# nrf5002 register map
Vendor: Nordic Semiconductor; Series: nRF50; File version: 1
CPU: CM0 r0p4, little endian, no MPU, no FPU, 2 interrupt priority bits, 32 interrupts
Registers are 32-bit, read-write, reset 0x0 unless marked. A register's access mark holds for its fields unless they carry their own. Offsets are from the block's base; [hi:lo] are bit positions; lines under a group give offsets from that group; 'fields as' and 'values as' point back to an identical list.

## REGULATORS — Regulator control
Base 0x40001000; alternate view of OSCILLATORS
0x434 DISABLEHPBOR wo — Enable or disable HPBOR
  [0] DISABLE
    0=Enabled (Enable HPBOR); 1=Disabled (Disable HPBOR)
0x500 SYSTEMOFF wo
  [0] SYSTEMOFF — Enable System OFF mode
    1=Enter (Enable System OFF mode)
0x50C POFSTAT ro — Power-fail comparator status register
  [0] COMPARATOR — Power-fail comparator status
    0=Above (Detected voltage is above VPOF threshold); 1=Below (Detected voltage is below VPOF threshold.)
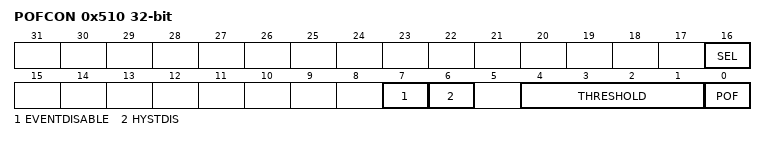
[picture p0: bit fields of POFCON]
0x510 POFCON — Power-fail comparator configuration
  [16] SEL — Power-fail comparator input selector
    0=VDD (POF measures or monitors the VDD supply voltage pin); 1=VMON (POF measures or monitors the VDDL pin.)
  [7] EVENTDISABLE — Disable the POFWARN power-fail warning event
    0=Enabled (POFWARN event is generated.); 1=Disabled (POFWARN event is not generated.)
  [6] HYSTDIS — Bypass power-fail comparator hysteresis
    0=Normal (Hysteresis active); 1=NoHyst (Hysteresis disabled)
  [4:1] THRESHOLD — Power-fail comparator threshold setting
    0=V17 (Set threshold to 1.7 V for VBUS, or 0.90 V for VDD); 1=V18 (Set threshold to 1.8 V for VBUS, or 0.95 V for VDD); 2=V19 (Set threshold to 1.9 V for VBUS, or 1.00 V for VDD); 3=V20 (Set threshold to 2.0 V for VBUS, or 1.05 V for VDD); 4=V21 (Set threshold to 2.1 V for VBUS, or 1.10 V for VDD); 5=V22 (Set threshold to 2.2 V for VBUS, or 1.15 V for VDD); 6=V23 (Set threshold to 2.3 V for VBUS, or 1.20 V for VDD); 7=V24 (Set threshold to 2.4 V for VBUS, or 1.25 V for VDD); 8=V25 (Set threshold to 2.5 V for VBUS, or 1.30 V for VDD); 9=V26 (Set threshold to 2.6 V for VBUS, or 1.35 V for VDD); 10=V27 (Set threshold to 2.7 V for VBUS, or 1.40 V for VDD); 11=V28 (Set threshold to 2.8 V for VBUS, or 1.45 V for VDD); 12=V29 (Set threshold to 2.9 V for VBUS, or 1.50 V for VDD); 13=V30 (Set threshold to 3.0 V for VBUS, or 1.55 V for VDD); 14=V31 (Set threshold to 3.1 V for VBUS, or 1.60 V for VDD); 15=V32 (Set threshold to 3.2 V for VBUS, or 1.65 V for VDD)
  [0] POF — Enable or disable power-fail comparator
    0=Disabled; 1=Enabled
0x514 IGNOREDAPCPWRREGMODE wo — Ignore DAPCP power mode
  [0] IGNOREDAPCPWRREGMODE — Ignore power request from debugger
    0=Do not ignore power request from debugger; 1=Ignore power request from debugger
0x518 RSTVTHTRIM — Threshold trim, power-on reset
  [4:0] RSTVTHTRIM
0x520 BGREFTRIM — Master bias bandgap trim
  [3:0] BGREFTRIM — Threshold trim, brown-out reset for VDDL battery
0x588 ATEPOWER reset 0x1 — Analog test bus control for power modules
0x58C VREFULPTRIM — Trim value of VREF_ULP
  [3:0] VREFULPTRIM — Trim value of VREF_ULP Default 4'b0011
0x5E8 FORCEVBUSDET — Force VBUS detection indication
  [1:0] FORCEVBUSDET — Force VBUS detection indication, overriding the analog detection circuitry
    0=Do not force VBUS detection output; 1=ForceNoVbusDet (Force detection output to 'no VBUS present'); 2=DoNotForce2 (Do not force VBUS detection output (same effect as DoNotForce)); 3=ForceVbusDet (Force detection output to 'VBUS present')
0x900 VREGANA group — Unspecified
  0x00 VOUT — Control the output voltage
    [1:0] VOUT — Output voltage
      0=1.0 V; 1=1.05 V; 2=1.10 V; 3=1.20 V
  0x04 DCDCEN — Enable DC/DC operation of the regulator
    [0] DCDCEN — Enable or disable DC/DC converter
      0=Disabled; 1=Enabled
  0x08 ENFORCEPWRREGMODE — Enable forcing of power mode in power regulator
    [0] ENFORCEPWRREGMODE
      0=Disabled (Power regulator forcing off); 1=Enabled (Power regulator mode forced to value given by FORCEREGMODE)
  0x0C FORCEREGMODE — Backdoor register for manual selection of power mode
    [2:0] FORCEREGMODE — Force regulator mode to value
      0=Ext (Force external); 1=ULP (Force ULP mode); 2=LDO (Force LDO mode); 3=DCDC (Force DC/DC mode); 4=REF (Force REF mode)
  0x10 CURRENTPWRREGMODE ro — Current mode in the power regulator
    [3:0] CURRENTPWRREGMODE
      0=Ext (External); 2=DCDC; 3=REF; 4=LDO (ULP DC/DC); 6=LDO_DCDC; 7=LDO_REF; 8=ULP; 10=DCDC_ULP (ULP DC/DC); 11=REF_ULP; 12=ULP_LDO (ULP DC/DC)
  0x14 TESTLOAD — Test load setting
    [2:0] TESTLOAD — Output load configuration (for test purposes)
      0=Normal operation (default); 1=1mATestLoad; 2=20mATestLoad
  0x18 ULPCAL — Calibration of ULP regulator
    [3:0] CAL — Calibration value
  0x1C DEBUGLVLP — Debug register - control spare signals in LVLP
    [13:0] DEBUGLVLP — Connected to TBD
  0x24 BUCKCALMAXILIM
    [1:0] CALMAXILIM
  0x28 BUCKCALPWM
    [4:0] CALPWM
  0x2C BUCKPFMEN reset 0x1 — PFM enable register
    [0] PFMEN — Enable or disable PFM
      0=Disabled (Disable PFM); 1=Enabled (Enable PFM (default))
  0x30 BUCKPFMCAL
    [3:0] PFMCAL
  0x34 BUCKPFMICMPCAL
    [2:0] PFMICMPCAL
  0x38 BUCKPFMICMPCOUNT
    [15:0] PFMICMPCOUNT
  0x3C PWRREGTHRESHOLD — Set threshold value of power regulator
    [6:0] PWRREGTHRESHOLD — Sets the threshold value of power regulator
  0x40 AVOIDULP reset 0x1 — Backdoor to avoid ULP mode
    [0] ENABLE
      0=Default (FSM will enter ULP mode if no power requests are present.); 1=AvoidUlp (Avoids ULP mode. By also setting disableDcdcDvdd=0 and disablePfmDvdd=0, PFM mode will be used as the lowest power regulator state.)
0xA00 VREGMAIN group — Unspecified
  0x00 VOUT — Control the output voltage
    [3:0] VOUT — Output voltage
  0x04 ULPALWAYSON reset 0x1 — Keep ULP regulator on at all times
    [0] ULPALWAYSON
      0=Disabled (ULP regulator turned off in LDO modes); 1=Enabled (ULP regulator always on)
  0x08 ENFORCEPWRREGMODE — Enable forcing of power mode in power regulator
    fields as VREGANA.ENFORCEPWRREGMODE
  0x0C FORCEREGMODE — Backdoor register for manual selection of power mode
    fields as VREGANA.FORCEREGMODE
  0x10 CURRENTPWRREGMODE ro — Current mode in the power regulator
    fields as VREGANA.CURRENTPWRREGMODE
  0x14 PWRREGICMPTIMER — Control the stay-alive time for the current comparator
    [15:0] COUNT
  0x18 TESTLOAD — Test load setting
    [2:0] TESTLOAD — Output load configuration for test purposes
      0=Normal operation (default); 1=1mATestLoad; 2=20mATestLoad
  0x20 ULPCAL — Calibration of ULP regulator
    [3:0] CAL — Calibration value
  0x24 ULPICMPCAL — Calibration of current comparator on ULP regulator
    [2:0] CAL
  0x28 BYPASS — Bypass control
    [0] CAL
      0=NormalMode (Normal operation (default)); 1=BypassMode (Output voltage is 30 mV lower than input voltage)
0xEE4 DISABLEPACSYSTEMOFFACK wo — Enable or disable System OFF ack from PAC
  [0] DISABLE
    0=Enabled (Enable ack); 1=Disabled (Disable ack)
0xEE8 DISABLESRAMSYSTEMOFFACK wo — Enable or disable System OFF ack from SRAM
  [0] DISABLE
    0=Enabled (Enable ack); 1=Disabled (Disable ack)
0xEEC DISABLENVMSYSTEMOFFACK wo — Enable or disable System OFF ack from NVM
  [0] DISABLE
    0=Enabled (Enable ack); 1=Disabled (Disable ack)
